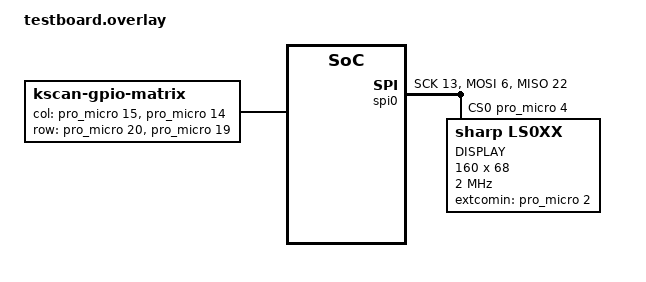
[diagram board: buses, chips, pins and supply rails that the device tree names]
/*
 * Copyright (c) 2020 The ZMK Contributors
 *
 * SPDX-License-Identifier: MIT
 */

/ {
    chosen {
        zmk,kscan = &kscan0;
    };

    kscan0: kscan_0 {
        compatible = "zmk,kscan-gpio-matrix";
        label = "KSCAN";
        diode-direction = "col2row";

        col-gpios
            = <&pro_micro 15 GPIO_ACTIVE_HIGH>
            , <&pro_micro 14 GPIO_ACTIVE_HIGH>
            ;

        row-gpios
            = <&pro_micro 20 (GPIO_ACTIVE_HIGH | GPIO_PULL_DOWN)>
            , <&pro_micro 19 (GPIO_ACTIVE_HIGH | GPIO_PULL_DOWN)>
            ;
    };
        
};  
    
&spi0 {
    status = "okay";
    compatible = "nordic,nrf-spim";
    sck-pin = <13>;
    miso-pin = <22>;
    mosi-pin = <6>;
    cs-gpios = <&pro_micro 4 GPIO_ACTIVE_HIGH>;

	ls0xx@0 {
		compatible = "sharp,ls0xx";
		label = "DISPLAY";
		spi-max-frequency = <2000000>;
		reg = <0>;
		width = <160>;
		height = <68>;
		extcomin-gpios = <&pro_micro 2 GPIO_ACTIVE_HIGH>;
		extcomin-frequency = <60>;
	};
};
